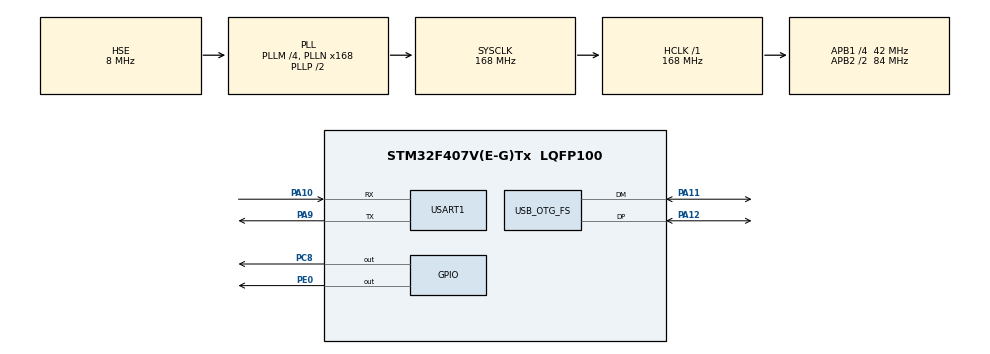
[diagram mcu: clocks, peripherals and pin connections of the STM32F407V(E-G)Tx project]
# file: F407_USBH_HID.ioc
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Mcu.Family=STM32F4
Mcu.Name=STM32F407V(E-G)Tx
Mcu.Package=LQFP100
NVIC.OTG_FS_IRQn=true\:0\:0\:false\:false\:true\:false\:true\:true
NVIC.PriorityGroup=NVIC_PRIORITYGROUP_4
PA10.Mode=Asynchronous
PA10.Signal=USART1_RX
PA11.Mode=Host_Only
PA11.Signal=USB_OTG_FS_DM
PA12.Mode=Host_Only
PA12.Signal=USB_OTG_FS_DP
PA9.Mode=Asynchronous
PA9.Signal=USART1_TX
PC8.Signal=GPIO_Output
PE0.Signal=GPIO_Output
PH0-OSC_IN.Mode=HSE-External-Oscillator
PH0-OSC_IN.Signal=RCC_OSC_IN
PH1-OSC_OUT.Mode=HSE-External-Oscillator
PH1-OSC_OUT.Signal=RCC_OSC_OUT
ProjectManager.HeapSize=0x400
ProjectManager.StackSize=0x400
ProjectManager.TargetToolchain=STM32CubeIDE
RCC.48MHZClocksFreq_Value=48000000
RCC.AHBFreq_Value=168000000
RCC.APB1CLKDivider=RCC_HCLK_DIV4
RCC.APB1Freq_Value=42000000
RCC.APB1TimFreq_Value=84000000
RCC.APB2CLKDivider=RCC_HCLK_DIV2
RCC.APB2Freq_Value=84000000
RCC.APB2TimFreq_Value=168000000
RCC.CortexFreq_Value=168000000
RCC.HCLKFreq_Value=168000000
RCC.HSE_VALUE=8000000
RCC.HSI_VALUE=16000000
RCC.LSE_VALUE=32768
RCC.PLLM=4
RCC.PLLN=168
RCC.PLLQ=7
RCC.SYSCLKFreq_VALUE=168000000
RCC.SYSCLKSource=RCC_SYSCLKSOURCE_PLLCLK
RCC.VCOOutputFreq_Value=336000000
USART1.VirtualMode=VM_ASYNC
USB_HOST.BSP.number=1
USB_HOST.USBH_DEBUG_LEVEL-HID_FS=3
USB_HOST.USBH_HandleTypeDef-HID_FS=hUsbHostFS
USB_HOST.VirtualModeFS=Hid
USB_HOST0.BSP.STBoard=false
USB_HOST0.BSP.api=Unknown
USB_HOST0.BSP.instance=PC8
USB_HOST0.BSP.ip=GPIO
USB_HOST0.BSP.mode=Output
USB_HOST0.BSP.name=Drive_VBUS_FS
USB_HOST0.BSP.solution=PC8
USB_OTG_FS.VirtualMode=Host_Only
USB_OTG_FS.phy_itface=HCD_PHY_EMBEDDED
VP_USB_HOST_VS_USB_HOST_HID_FS.Mode=HID_FS
board=custom

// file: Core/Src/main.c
/* USER CODE BEGIN Header */
/**
 ******************************************************************************
 * @file           : main.c
 * @brief          : Main program body
 ******************************************************************************
 * @attention
 *
 * Copyright (c) 2023 STMicroelectronics.
 * All rights reserved.
 *
 * This software is licensed under terms that can be found in the LICENSE file
 * in the root directory of this software component.
 * If no LICENSE file comes with this software, it is provided AS-IS.
 *
 ******************************************************************************
 */
/* USER CODE END Header */
#include "main.h"
#include "usb_host.h"

/* USER CODE BEGIN Includes */
#include "log_uart.h"
/* USER CODE END Includes */

UART_HandleTypeDef huart1;

void SystemClock_Config(void);
static void MX_GPIO_Init(void);
static void MX_USART1_UART_Init(void);
void MX_USB_HOST_Process(void);

int main(void) {

	/* MCU Configuration--------------------------------------------------------*/

	/* Reset of all peripherals, Initializes the Flash interface and the Systick. */
	HAL_Init();

	/* Configure the system clock */
	SystemClock_Config();

	/* Initialize all configured peripherals */
	MX_GPIO_Init();
	MX_USART1_UART_Init();
	MX_USB_HOST_Init();
	/* USER CODE BEGIN 2 */
	UsrLog("\033[2J\033[H");
	UsrLog(" ");
	UsrLog("App start");
	UsrLog("MCU-ID %08lX", DBGMCU->IDCODE);
	/* USER CODE END 2 */

	/* Infinite loop */
	while (1) {
		MX_USB_HOST_Process();

	}
}

void SystemClock_Config(void) {
	RCC_OscInitTypeDef RCC_OscInitStruct = { 0 };
	RCC_ClkInitTypeDef RCC_ClkInitStruct = { 0 };

	/** Configure the main internal regulator output voltage
	 */
	__HAL_RCC_PWR_CLK_ENABLE();
	__HAL_PWR_VOLTAGESCALING_CONFIG(PWR_REGULATOR_VOLTAGE_SCALE1);

	/** Initializes the RCC Oscillators according to the specified parameters
	 * in the RCC_OscInitTypeDef structure.
	 */
	RCC_OscInitStruct.OscillatorType = RCC_OSCILLATORTYPE_HSE;
	RCC_OscInitStruct.HSEState = RCC_HSE_ON;
	RCC_OscInitStruct.PLL.PLLState = RCC_PLL_ON;
	RCC_OscInitStruct.PLL.PLLSource = RCC_PLLSOURCE_HSE;
	RCC_OscInitStruct.PLL.PLLM = 4;
	RCC_OscInitStruct.PLL.PLLN = 168;
	RCC_OscInitStruct.PLL.PLLP = RCC_PLLP_DIV2;
	RCC_OscInitStruct.PLL.PLLQ = 7;
	if (HAL_RCC_OscConfig(&RCC_OscInitStruct) != HAL_OK) {
		Error_Handler();
	}

	/** Initializes the CPU, AHB and APB buses clocks
	 */
	RCC_ClkInitStruct.ClockType = RCC_CLOCKTYPE_HCLK | RCC_CLOCKTYPE_SYSCLK
			| RCC_CLOCKTYPE_PCLK1 | RCC_CLOCKTYPE_PCLK2;
	RCC_ClkInitStruct.SYSCLKSource = RCC_SYSCLKSOURCE_PLLCLK;
	RCC_ClkInitStruct.AHBCLKDivider = RCC_SYSCLK_DIV1;
	RCC_ClkInitStruct.APB1CLKDivider = RCC_HCLK_DIV4;
	RCC_ClkInitStruct.APB2CLKDivider = RCC_HCLK_DIV2;

	if (HAL_RCC_ClockConfig(&RCC_ClkInitStruct, FLASH_LATENCY_5) != HAL_OK) {
		Error_Handler();
	}
}

static void MX_USART1_UART_Init(void) {

	huart1.Instance = USART1;
	huart1.Init.BaudRate = 115200;
	huart1.Init.WordLength = UART_WORDLENGTH_8B;
	huart1.Init.StopBits = UART_STOPBITS_1;
	huart1.Init.Parity = UART_PARITY_NONE;
	huart1.Init.Mode = UART_MODE_TX_RX;
	huart1.Init.HwFlowCtl = UART_HWCONTROL_NONE;
	huart1.Init.OverSampling = UART_OVERSAMPLING_16;
	if (HAL_UART_Init(&huart1) != HAL_OK) {
		Error_Handler();
	}

}

static void MX_GPIO_Init(void) {
	GPIO_InitTypeDef GPIO_InitStruct = { 0 };

	/* GPIO Ports Clock Enable */
	__HAL_RCC_GPIOH_CLK_ENABLE();
	__HAL_RCC_GPIOC_CLK_ENABLE();
	__HAL_RCC_GPIOA_CLK_ENABLE();
	__HAL_RCC_GPIOE_CLK_ENABLE();

	/*Configure GPIO pin Output Level */
	HAL_GPIO_WritePin(GPIOC, GPIO_PIN_8, GPIO_PIN_RESET);

	/*Configure GPIO pin Output Level */
	HAL_GPIO_WritePin(GPIOE, GPIO_PIN_0, GPIO_PIN_RESET);

	/*Configure GPIO pin : PC8 */
	GPIO_InitStruct.Pin = GPIO_PIN_8;
	GPIO_InitStruct.Mode = GPIO_MODE_OUTPUT_PP;
	GPIO_InitStruct.Pull = GPIO_NOPULL;
	GPIO_InitStruct.Speed = GPIO_SPEED_FREQ_LOW;
	HAL_GPIO_Init(GPIOC, &GPIO_InitStruct);

	/*Configure GPIO pin : PE0 */
	GPIO_InitStruct.Pin = GPIO_PIN_0;
	GPIO_InitStruct.Mode = GPIO_MODE_OUTPUT_PP;
	GPIO_InitStruct.Pull = GPIO_NOPULL;
	GPIO_InitStruct.Speed = GPIO_SPEED_FREQ_LOW;
	HAL_GPIO_Init(GPIOE, &GPIO_InitStruct);

}

void Error_Handler(void) {
	__disable_irq();
	while (1) {
	}
}
